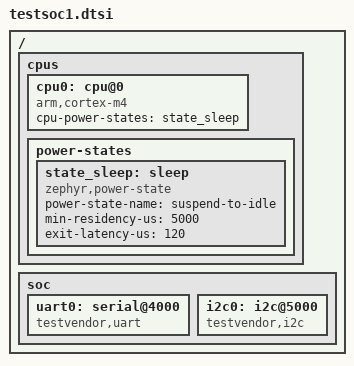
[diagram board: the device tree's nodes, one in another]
#include <testvendor/testfam_common.dtsi>
/ {
    cpus {
        cpu0: cpu@0 {
            compatible = "arm,cortex-m4";
            cpu-power-states = <&state_sleep>;
        };
        power-states {
            state_sleep: sleep {
                compatible = "zephyr,power-state";
                power-state-name = "suspend-to-idle";
                min-residency-us = <5000>;
                exit-latency-us = <120>;
            };
        };
    };
    soc {
        uart0: serial@4000 { compatible = "testvendor,uart"; };
        i2c0: i2c@5000 { compatible = "testvendor,i2c", "generic-i2c"; };
    };
};
